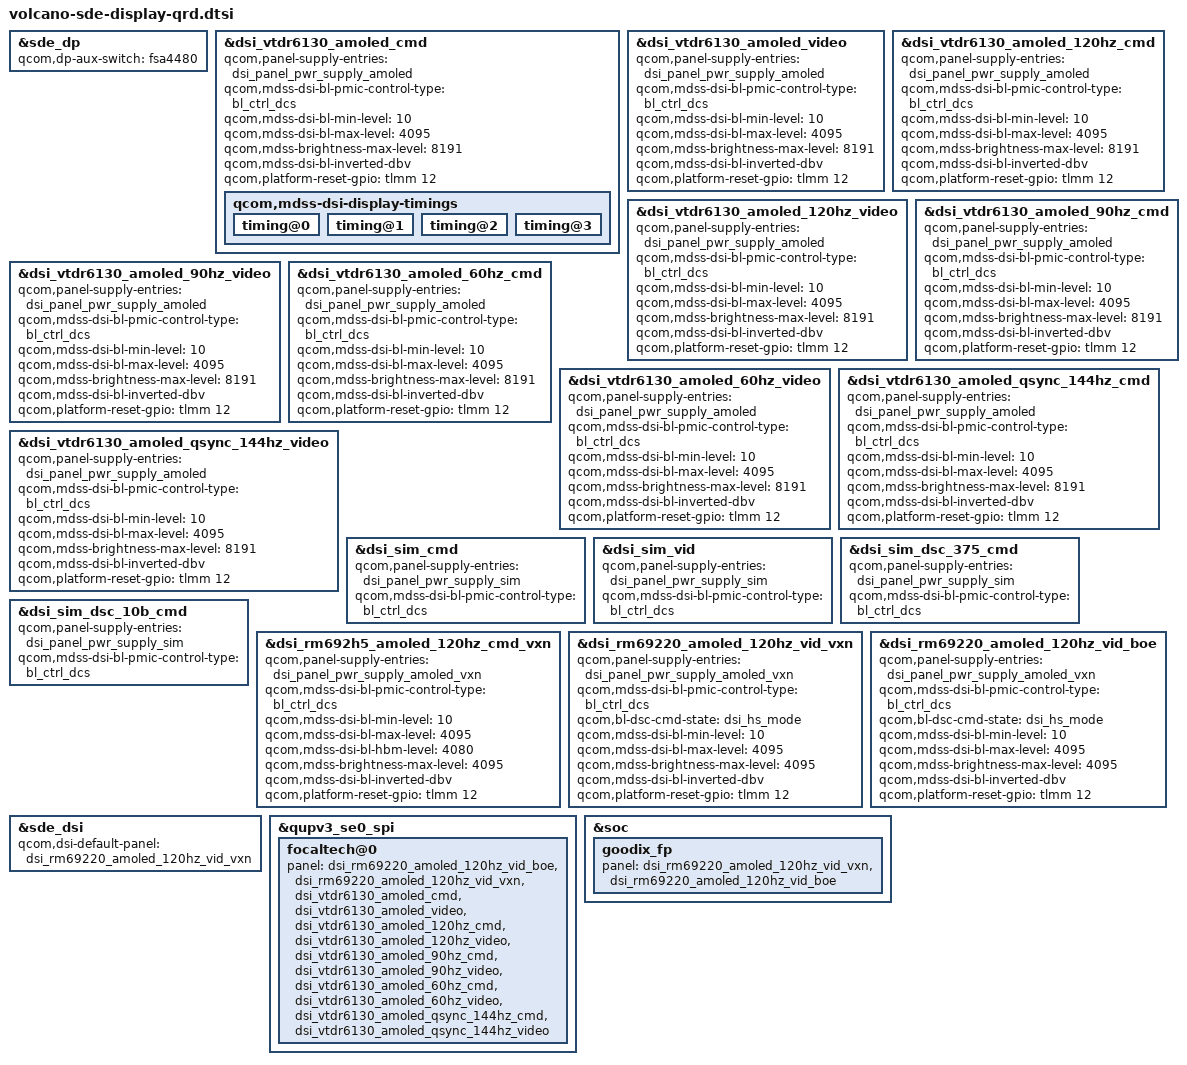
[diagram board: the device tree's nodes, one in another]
#include "volcano-sde-display.dtsi"

&sde_dp {
	status = "ok";

	qcom,dp-aux-switch = <&fsa4480>;
};

&dsi_vtdr6130_amoled_cmd {
	qcom,panel-supply-entries = <&dsi_panel_pwr_supply_amoled>;
	qcom,mdss-dsi-bl-pmic-control-type = "bl_ctrl_dcs";
	qcom,mdss-dsi-bl-min-level = <10>;
	qcom,mdss-dsi-bl-max-level = <4095>;
	qcom,mdss-brightness-max-level = <8191>;
	qcom,mdss-dsi-bl-inverted-dbv;
	qcom,platform-reset-gpio = <&tlmm 12 0>;

	qcom,mdss-dsi-display-timings {
		timing@0 {
			/delete-property/ qcom,partial-update-enabled;
		};

		timing@1 {
			/delete-property/ qcom,partial-update-enabled;
		};

		timing@2 {
			/delete-property/ qcom,partial-update-enabled;
		};

		timing@3 {
			/delete-property/ qcom,partial-update-enabled;
		};
	};
};

&dsi_vtdr6130_amoled_video {
	qcom,panel-supply-entries = <&dsi_panel_pwr_supply_amoled>;
	qcom,mdss-dsi-bl-pmic-control-type = "bl_ctrl_dcs";
	qcom,mdss-dsi-bl-min-level = <10>;
	qcom,mdss-dsi-bl-max-level = <4095>;
	qcom,mdss-brightness-max-level = <8191>;
	qcom,mdss-dsi-bl-inverted-dbv;
	qcom,platform-reset-gpio = <&tlmm 12 0>;
};

&dsi_vtdr6130_amoled_120hz_cmd {
	qcom,panel-supply-entries = <&dsi_panel_pwr_supply_amoled>;
	qcom,mdss-dsi-bl-pmic-control-type = "bl_ctrl_dcs";
	qcom,mdss-dsi-bl-min-level = <10>;
	qcom,mdss-dsi-bl-max-level = <4095>;
	qcom,mdss-brightness-max-level = <8191>;
	qcom,mdss-dsi-bl-inverted-dbv;
	qcom,platform-reset-gpio = <&tlmm 12 0>;
};

&dsi_vtdr6130_amoled_120hz_video {
	qcom,panel-supply-entries = <&dsi_panel_pwr_supply_amoled>;
	qcom,mdss-dsi-bl-pmic-control-type = "bl_ctrl_dcs";
	qcom,mdss-dsi-bl-min-level = <10>;
	qcom,mdss-dsi-bl-max-level = <4095>;
	qcom,mdss-brightness-max-level = <8191>;
	qcom,mdss-dsi-bl-inverted-dbv;
	qcom,platform-reset-gpio = <&tlmm 12 0>;
};

&dsi_vtdr6130_amoled_90hz_cmd {
	qcom,panel-supply-entries = <&dsi_panel_pwr_supply_amoled>;
	qcom,mdss-dsi-bl-pmic-control-type = "bl_ctrl_dcs";
	qcom,mdss-dsi-bl-min-level = <10>;
	qcom,mdss-dsi-bl-max-level = <4095>;
	qcom,mdss-brightness-max-level = <8191>;
	qcom,mdss-dsi-bl-inverted-dbv;
	qcom,platform-reset-gpio = <&tlmm 12 0>;
};

&dsi_vtdr6130_amoled_90hz_video {
	qcom,panel-supply-entries = <&dsi_panel_pwr_supply_amoled>;
	qcom,mdss-dsi-bl-pmic-control-type = "bl_ctrl_dcs";
	qcom,mdss-dsi-bl-min-level = <10>;
	qcom,mdss-dsi-bl-max-level = <4095>;
	qcom,mdss-brightness-max-level = <8191>;
	qcom,mdss-dsi-bl-inverted-dbv;
	qcom,platform-reset-gpio = <&tlmm 12 0>;
};

&dsi_vtdr6130_amoled_60hz_cmd {
	qcom,panel-supply-entries = <&dsi_panel_pwr_supply_amoled>;
	qcom,mdss-dsi-bl-pmic-control-type = "bl_ctrl_dcs";
	qcom,mdss-dsi-bl-min-level = <10>;
	qcom,mdss-dsi-bl-max-level = <4095>;
	qcom,mdss-brightness-max-level = <8191>;
	qcom,mdss-dsi-bl-inverted-dbv;
	qcom,platform-reset-gpio = <&tlmm 12 0>;
};

&dsi_vtdr6130_amoled_60hz_video {
	qcom,panel-supply-entries = <&dsi_panel_pwr_supply_amoled>;
	qcom,mdss-dsi-bl-pmic-control-type = "bl_ctrl_dcs";
	qcom,mdss-dsi-bl-min-level = <10>;
	qcom,mdss-dsi-bl-max-level = <4095>;
	qcom,mdss-brightness-max-level = <8191>;
	qcom,mdss-dsi-bl-inverted-dbv;
	qcom,platform-reset-gpio = <&tlmm 12 0>;
};

&dsi_vtdr6130_amoled_qsync_144hz_cmd {
	qcom,panel-supply-entries = <&dsi_panel_pwr_supply_amoled>;
	qcom,mdss-dsi-bl-pmic-control-type = "bl_ctrl_dcs";
	qcom,mdss-dsi-bl-min-level = <10>;
	qcom,mdss-dsi-bl-max-level = <4095>;
	qcom,mdss-brightness-max-level = <8191>;
	qcom,mdss-dsi-bl-inverted-dbv;
	qcom,platform-reset-gpio = <&tlmm 12 0>;
};

&dsi_vtdr6130_amoled_qsync_144hz_video {
	qcom,panel-supply-entries = <&dsi_panel_pwr_supply_amoled>;
	qcom,mdss-dsi-bl-pmic-control-type = "bl_ctrl_dcs";
	qcom,mdss-dsi-bl-min-level = <10>;
	qcom,mdss-dsi-bl-max-level = <4095>;
	qcom,mdss-brightness-max-level = <8191>;
	qcom,mdss-dsi-bl-inverted-dbv;
	qcom,platform-reset-gpio = <&tlmm 12 0>;
};

&dsi_sim_cmd {
	qcom,panel-supply-entries = <&dsi_panel_pwr_supply_sim>;
	qcom,mdss-dsi-bl-pmic-control-type = "bl_ctrl_dcs";
};

&dsi_sim_vid {
	qcom,panel-supply-entries = <&dsi_panel_pwr_supply_sim>;
	qcom,mdss-dsi-bl-pmic-control-type = "bl_ctrl_dcs";
};

&dsi_sim_dsc_375_cmd {
	qcom,panel-supply-entries = <&dsi_panel_pwr_supply_sim>;
	qcom,mdss-dsi-bl-pmic-control-type = "bl_ctrl_dcs";
};

&dsi_sim_dsc_10b_cmd {
	qcom,panel-supply-entries = <&dsi_panel_pwr_supply_sim>;
	qcom,mdss-dsi-bl-pmic-control-type = "bl_ctrl_dcs";
};

&dsi_rm692h5_amoled_120hz_cmd_vxn {
	qcom,panel-supply-entries = <&dsi_panel_pwr_supply_amoled_vxn>;
	qcom,mdss-dsi-bl-pmic-control-type = "bl_ctrl_dcs";
	qcom,mdss-dsi-bl-min-level = <10>;
	qcom,mdss-dsi-bl-max-level = <4095>;
	qcom,mdss-dsi-bl-hbm-level = <4080>;
	qcom,mdss-brightness-max-level = <4095>;
	qcom,mdss-dsi-bl-inverted-dbv;
	qcom,platform-reset-gpio = <&tlmm 12 0>;
};

&dsi_rm69220_amoled_120hz_vid_vxn {
	qcom,panel-supply-entries = <&dsi_panel_pwr_supply_amoled_vxn>;
	qcom,mdss-dsi-bl-pmic-control-type = "bl_ctrl_dcs";
	qcom,bl-dsc-cmd-state = "dsi_hs_mode";
	qcom,mdss-dsi-bl-min-level = <10>;
	qcom,mdss-dsi-bl-max-level = <4095>;
	qcom,mdss-brightness-max-level = <4095>;
	qcom,mdss-dsi-bl-inverted-dbv;
	qcom,platform-reset-gpio = <&tlmm 12 0>;
};

&dsi_rm69220_amoled_120hz_vid_boe {
	qcom,panel-supply-entries = <&dsi_panel_pwr_supply_amoled_vxn>;
	qcom,mdss-dsi-bl-pmic-control-type = "bl_ctrl_dcs";
	qcom,bl-dsc-cmd-state = "dsi_hs_mode";
	qcom,mdss-dsi-bl-min-level = <10>;
	qcom,mdss-dsi-bl-max-level = <4095>;
	qcom,mdss-brightness-max-level = <4095>;
	qcom,mdss-dsi-bl-inverted-dbv;
	qcom,platform-reset-gpio = <&tlmm 12 0>;
};

&sde_dsi {
	qcom,dsi-default-panel = <&dsi_rm69220_amoled_120hz_vid_vxn>;
};

&qupv3_se0_spi {
	focaltech@0 {
		panel = <&dsi_rm69220_amoled_120hz_vid_boe
			&dsi_rm69220_amoled_120hz_vid_vxn
			&dsi_vtdr6130_amoled_cmd
			&dsi_vtdr6130_amoled_video
			&dsi_vtdr6130_amoled_120hz_cmd
			&dsi_vtdr6130_amoled_120hz_video
			&dsi_vtdr6130_amoled_90hz_cmd
			&dsi_vtdr6130_amoled_90hz_video
			&dsi_vtdr6130_amoled_60hz_cmd
			&dsi_vtdr6130_amoled_60hz_video
			&dsi_vtdr6130_amoled_qsync_144hz_cmd
			&dsi_vtdr6130_amoled_qsync_144hz_video>;
	};
};

&soc {
	goodix_fp {
		panel = <&dsi_rm69220_amoled_120hz_vid_vxn
			&dsi_rm69220_amoled_120hz_vid_boe>;
	};
};
